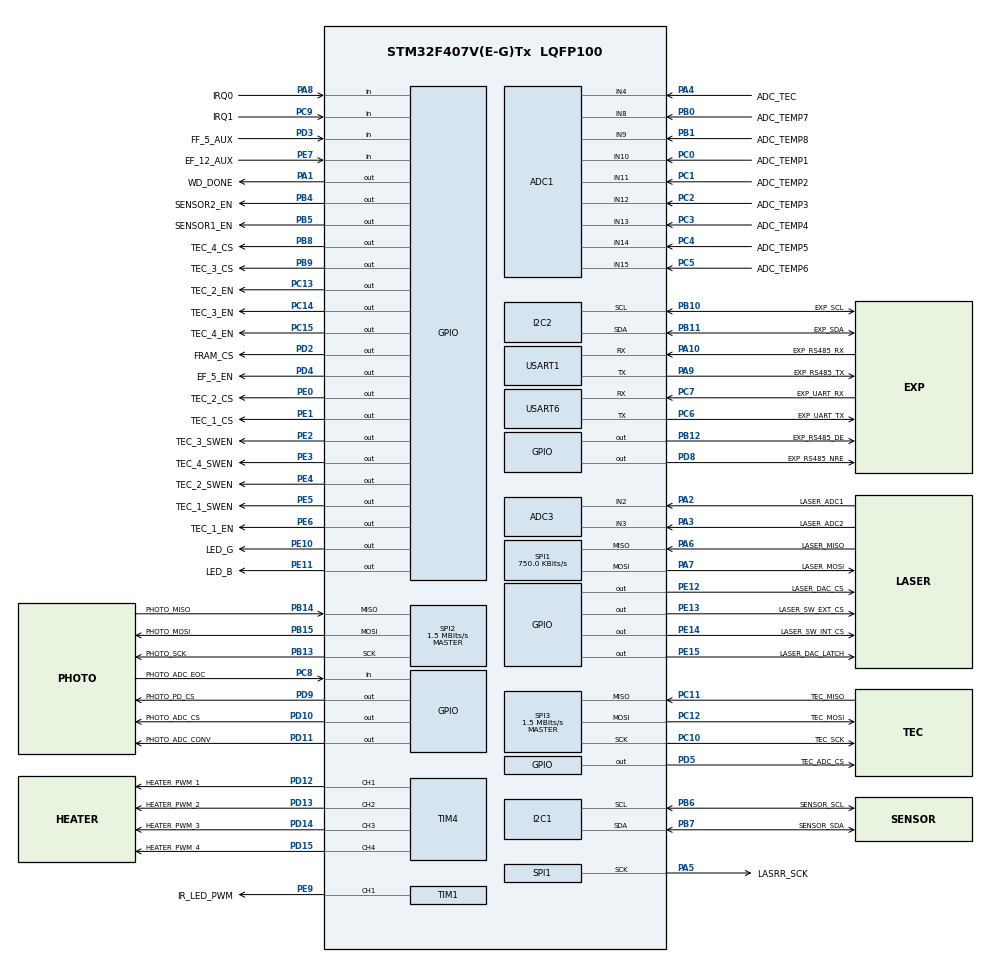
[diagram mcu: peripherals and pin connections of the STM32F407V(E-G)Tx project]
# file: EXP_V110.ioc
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ADC1.Channel-0\#ChannelRegularConversion=ADC_CHANNEL_10
ADC1.Channel-1\#ChannelRegularConversion=ADC_CHANNEL_11
ADC1.Channel-2\#ChannelRegularConversion=ADC_CHANNEL_12
ADC1.Channel-3\#ChannelRegularConversion=ADC_CHANNEL_13
ADC1.Channel-4\#ChannelRegularConversion=ADC_CHANNEL_14
ADC1.Channel-5\#ChannelRegularConversion=ADC_CHANNEL_15
ADC1.Channel-6\#ChannelRegularConversion=ADC_CHANNEL_8
ADC1.Channel-7\#ChannelRegularConversion=ADC_CHANNEL_9
ADC1.ContinuousConvMode=ENABLE
ADC1.DMAContinuousRequests=ENABLE
ADC1.EOCSelection=ADC_EOC_SEQ_CONV
ADC1.InjNumberOfConversion=0
ADC1.NbrOfConversion=8
ADC1.NbrOfConversionFlag=1
ADC1.Rank-0\#ChannelRegularConversion=1
ADC1.Rank-1\#ChannelRegularConversion=2
ADC1.Rank-2\#ChannelRegularConversion=3
ADC1.Rank-3\#ChannelRegularConversion=4
ADC1.Rank-4\#ChannelRegularConversion=5
ADC1.Rank-5\#ChannelRegularConversion=6
ADC1.Rank-6\#ChannelRegularConversion=7
ADC1.Rank-7\#ChannelRegularConversion=8
ADC1.SamplingTime-0\#ChannelRegularConversion=ADC_SAMPLETIME_15CYCLES
ADC1.SamplingTime-1\#ChannelRegularConversion=ADC_SAMPLETIME_15CYCLES
ADC1.SamplingTime-2\#ChannelRegularConversion=ADC_SAMPLETIME_15CYCLES
ADC1.SamplingTime-3\#ChannelRegularConversion=ADC_SAMPLETIME_15CYCLES
ADC1.SamplingTime-4\#ChannelRegularConversion=ADC_SAMPLETIME_15CYCLES
ADC1.SamplingTime-5\#ChannelRegularConversion=ADC_SAMPLETIME_15CYCLES
ADC1.SamplingTime-6\#ChannelRegularConversion=ADC_SAMPLETIME_15CYCLES
ADC1.SamplingTime-7\#ChannelRegularConversion=ADC_SAMPLETIME_15CYCLES
ADC1.ScanConvMode=ENABLE
ADC1.master=1
ADC3.Channel-0\#ChannelRegularConversion=ADC_CHANNEL_2
ADC3.NbrOfConversionFlag=1
ADC3.Rank-0\#ChannelRegularConversion=1
ADC3.SamplingTime-0\#ChannelRegularConversion=ADC_SAMPLETIME_3CYCLES
Dma.ADC1.0.Direction=DMA_PERIPH_TO_MEMORY
Dma.ADC1.0.FIFOMode=DMA_FIFOMODE_DISABLE
Dma.ADC1.0.Instance=DMA2_Stream0
Dma.ADC1.0.MemDataAlignment=DMA_MDATAALIGN_HALFWORD
Dma.ADC1.0.MemInc=DMA_MINC_ENABLE
Dma.ADC1.0.Mode=DMA_CIRCULAR
Dma.ADC1.0.PeriphDataAlignment=DMA_PDATAALIGN_HALFWORD
Dma.ADC1.0.PeriphInc=DMA_PINC_DISABLE
Dma.ADC1.0.Priority=DMA_PRIORITY_MEDIUM
Dma.Request0=ADC1
I2C2.OwnAddress=0x12
Mcu.Family=STM32F4
Mcu.Name=STM32F407V(E-G)Tx
Mcu.Package=LQFP100
NVIC.DMA2_Stream0_IRQn=true\:0\:0\:false\:false\:true\:false\:true\:true
NVIC.I2C2_ER_IRQn=true\:0\:0\:false\:false\:true\:true\:true\:true
NVIC.I2C2_EV_IRQn=true\:0\:0\:false\:false\:true\:true\:true\:true
NVIC.PriorityGroup=NVIC_PRIORITYGROUP_4
NVIC.USART1_IRQn=true\:0\:0\:false\:false\:true\:true\:true\:true
NVIC.USART6_IRQn=true\:0\:0\:false\:false\:true\:true\:true\:true
PA0-WKUP.GPIO_Label=WD_WAKE
PA0-WKUP.Mode=SYS_WakeUp0
PA0-WKUP.Signal=SYS_WKUP
PA1.GPIO_Label=WD_DONE
PA1.Signal=GPIO_Output
PA10.GPIO_Label=EXP_RS485_RX
PA10.Mode=Asynchronous
PA10.Signal=USART1_RX
PA13.Mode=Serial_Wire
PA13.Signal=SYS_JTMS-SWDIO
PA14.Mode=Serial_Wire
PA14.Signal=SYS_JTCK-SWCLK
PA2.GPIO_Label=LASER_ADC1
PA2.Signal=ADCx_IN2
PA3.GPIO_Label=LASER_ADC2
PA3.Signal=ADCx_IN3
PA4.GPIO_Label=ADC_TEC
PA4.Signal=ADCx_IN4
PA5.GPIO_Label=LASRR_SCK
PA5.GPIO_PuPd=GPIO_NOPULL
PA5.Mode=Full_Duplex_Master
PA5.Signal=SPI1_SCK
PA6.GPIO_Label=LASER_MISO
PA6.GPIO_PuPd=GPIO_NOPULL
PA6.Mode=Full_Duplex_Master
PA6.Signal=SPI1_MISO
PA7.GPIO_Label=LASER_MOSI
PA7.GPIO_PuPd=GPIO_NOPULL
PA7.Mode=Full_Duplex_Master
PA7.Signal=SPI1_MOSI
PA8.GPIO_Label=IRQ0
PA8.Signal=GPIO_Input
PA9.GPIO_Label=EXP_RS485_TX
PA9.Mode=Asynchronous
PA9.Signal=USART1_TX
PB0.GPIO_Label=ADC_TEMP7
PB0.Signal=ADCx_IN8
PB1.GPIO_Label=ADC_TEMP8
PB1.Signal=ADCx_IN9
PB10.GPIO_Label=EXP_SCL
PB10.Mode=I2C
PB10.Signal=I2C2_SCL
PB11.GPIO_Label=EXP_SDA
PB11.Mode=I2C
PB11.Signal=I2C2_SDA
PB12.GPIO_Label=EXP_RS485_DE
PB12.PinState=GPIO_PIN_SET
PB12.Signal=GPIO_Output
PB13.GPIO_Label=PHOTO_SCK
PB13.Mode=Full_Duplex_Master
PB13.Signal=SPI2_SCK
PB14.GPIO_Label=PHOTO_MISO
PB14.Mode=Full_Duplex_Master
PB14.Signal=SPI2_MISO
PB15.GPIO_Label=PHOTO_MOSI
PB15.Mode=Full_Duplex_Master
PB15.Signal=SPI2_MOSI
PB4.GPIO_Label=SENSOR2_EN
PB4.Signal=GPIO_Output
PB5.GPIO_Label=SENSOR1_EN
PB5.Signal=GPIO_Output
PB6.GPIO_Label=SENSOR_SCL
PB6.Mode=I2C
PB6.Signal=I2C1_SCL
PB7.GPIO_Label=SENSOR_SDA
PB7.Mode=I2C
PB7.Signal=I2C1_SDA
PB8.GPIO_Label=TEC_4_CS
PB8.PinState=GPIO_PIN_SET
PB8.Signal=GPIO_Output
PB9.GPIO_Label=TEC_3_CS
PB9.PinState=GPIO_PIN_SET
PB9.Signal=GPIO_Output
PC0.GPIO_Label=ADC_TEMP1
PC0.Signal=ADCx_IN10
PC1.GPIO_Label=ADC_TEMP2
PC1.Signal=ADCx_IN11
PC10.GPIO_Label=TEC_SCK
PC10.Mode=Full_Duplex_Master
PC10.Signal=SPI3_SCK
PC11.GPIO_Label=TEC_MISO
PC11.Mode=Full_Duplex_Master
PC11.Signal=SPI3_MISO
PC12.GPIO_Label=TEC_MOSI
PC12.Mode=Full_Duplex_Master
PC12.Signal=SPI3_MOSI
PC13-ANTI_TAMP.GPIO_Label=TEC_2_EN
PC13-ANTI_TAMP.Signal=GPIO_Output
PC14-OSC32_IN.GPIO_Label=TEC_3_EN
PC14-OSC32_IN.Signal=GPIO_Output
PC15-OSC32_OUT.GPIO_Label=TEC_4_EN
PC15-OSC32_OUT.Signal=GPIO_Output
PC2.GPIO_Label=ADC_TEMP3
PC2.Signal=ADCx_IN12
PC3.GPIO_Label=ADC_TEMP4
PC3.Signal=ADCx_IN13
PC4.GPIO_Label=ADC_TEMP5
PC4.Signal=ADCx_IN14
PC5.GPIO_Label=ADC_TEMP6
PC5.Signal=ADCx_IN15
PC6.GPIO_Label=EXP_UART_TX
PC6.Mode=Asynchronous
PC6.Signal=USART6_TX
PC7.GPIO_Label=EXP_UART_RX
PC7.Mode=Asynchronous
PC7.Signal=USART6_RX
PC8.GPIO_Label=PHOTO_ADC_EOC
PC8.GPIO_PuPd=GPIO_PULLUP
PC8.Signal=GPIO_Input
PC9.GPIO_Label=IRQ1
PC9.Signal=GPIO_Input
PD10.GPIO_Label=PHOTO_ADC_CS
PD10.PinState=GPIO_PIN_SET
PD10.Signal=GPIO_Output
PD11.GPIO_Label=PHOTO_ADC_CONV
PD11.PinState=GPIO_PIN_SET
PD11.Signal=GPIO_Output
PD12.GPIO_Label=HEATER_PWM_1
PD12.Signal=S_TIM4_CH1
PD13.GPIO_Label=HEATER_PWM_2
PD13.Signal=S_TIM4_CH2
PD14.GPIO_Label=HEATER_PWM_3
PD14.Signal=S_TIM4_CH3
PD15.GPIO_Label=HEATER_PWM_4
PD15.Signal=S_TIM4_CH4
PD2.GPIO_Label=FRAM_CS
PD2.Signal=GPIO_Output
PD3.GPIO_Label=FF_5_AUX
PD3.Signal=GPIO_Input
PD4.GPIO_Label=EF_5_EN
PD4.Signal=GPIO_Output
PD5.GPIO_Label=TEC_ADC_CS
PD5.Signal=GPIO_Output
PD8.GPIO_Label=EXP_RS485_NRE
PD8.Signal=GPIO_Output
PD9.GPIO_Label=PHOTO_PD_CS
PD9.PinState=GPIO_PIN_SET
PD9.Signal=GPIO_Output
PE0.GPIO_Label=TEC_2_CS
PE0.PinState=GPIO_PIN_SET
PE0.Signal=GPIO_Output
PE1.GPIO_Label=TEC_1_CS
PE1.GPIO_PuPd=GPIO_NOPULL
PE1.PinState=GPIO_PIN_SET
PE1.Signal=GPIO_Output
PE10.GPIO_Label=LED_G
PE10.Signal=GPIO_Output
PE11.GPIO_Label=LED_B
PE11.Signal=GPIO_Output
PE12.GPIO_Label=LASER_DAC_CS
PE12.PinState=GPIO_PIN_SET
PE12.Signal=GPIO_Output
PE13.GPIO_Label=LASER_SW_EXT_CS
PE13.PinState=GPIO_PIN_SET
PE13.Signal=GPIO_Output
PE14.GPIO_Label=LASER_SW_INT_CS
PE14.PinState=GPIO_PIN_SET
PE14.Signal=GPIO_Output
PE15.GPIO_Label=LASER_DAC_LATCH
PE15.PinState=GPIO_PIN_SET
PE15.Signal=GPIO_Output
PE2.GPIO_Label=TEC_3_SWEN
PE2.GPIO_PuPd=GPIO_PULLDOWN
PE2.Signal=GPIO_Output
PE3.GPIO_Label=TEC_4_SWEN
PE3.Signal=GPIO_Output
PE4.GPIO_Label=TEC_2_SWEN
PE4.Signal=GPIO_Output
PE5.GPIO_Label=TEC_1_SWEN
PE5.GPIO_PuPd=GPIO_PULLDOWN
PE5.Signal=GPIO_Output
PE6.GPIO_Label=TEC_1_EN
PE6.Signal=GPIO_Output
PE7.GPIO_Label=EF_12_AUX
PE7.Signal=GPIO_Input
PE9.GPIO_Label=IR_LED_PWM
PE9.Signal=S_TIM1_CH1
PH0-OSC_IN.Mode=HSE-External-Oscillator
PH0-OSC_IN.Signal=RCC_OSC_IN
PH1-OSC_OUT.Mode=HSE-External-Oscillator
PH1-OSC_OUT.Signal=RCC_OSC_OUT
ProjectManager.HeapSize=0x200
ProjectManager.StackSize=0x400
ProjectManager.TargetToolchain=STM32CubeIDE
RCC.48MHZClocksFreq_Value=36000000
RCC.AHBFreq_Value=24000000
RCC.APB1Freq_Value=24000000
RCC.APB1TimFreq_Value=24000000
RCC.APB2Freq_Value=24000000
RCC.APB2TimFreq_Value=24000000
RCC.CortexFreq_Value=24000000
RCC.HCLKFreq_Value=24000000
RCC.HSE_VALUE=8000000
RCC.HSI_VALUE=16000000
RCC.LSE_VALUE=32768
RCC.PLLM=4
RCC.PLLN=72
RCC.PLLP=RCC_PLLP_DIV6
RCC.PLLSourceVirtual=RCC_PLLSOURCE_HSE
RCC.SYSCLKFreq_VALUE=24000000
RCC.SYSCLKSource=RCC_SYSCLKSOURCE_PLLCLK
RCC.VCOOutputFreq_Value=144000000
SH.ADCx_IN10.0=ADC1_IN10,IN10
SH.ADCx_IN11.0=ADC1_IN11,IN11
SH.ADCx_IN12.0=ADC1_IN12,IN12
SH.ADCx_IN13.0=ADC1_IN13,IN13
SH.ADCx_IN14.0=ADC1_IN14,IN14
SH.ADCx_IN15.0=ADC1_IN15,IN15
SH.ADCx_IN2.0=ADC3_IN2,IN2
SH.ADCx_IN3.0=ADC3_IN3,IN3
SH.ADCx_IN4.0=ADC1_IN4,IN4
SH.ADCx_IN8.0=ADC1_IN8,IN8
SH.ADCx_IN9.0=ADC1_IN9,IN9
SH.S_TIM1_CH1.0=TIM1_CH1,PWM Generation1 CH1
SH.S_TIM4_CH1.0=TIM4_CH1,Output Compare1 CH1
SH.S_TIM4_CH2.0=TIM4_CH2,Output Compare2 CH2
SH.S_TIM4_CH3.0=TIM4_CH3,Output Compare3 CH3
SH.S_TIM4_CH4.0=TIM4_CH4,Output Compare4 CH4
SPI1.BaudRatePrescaler=SPI_BAUDRATEPRESCALER_32
SPI1.CLKPhase=SPI_PHASE_2EDGE
SPI1.CRCCalculation=SPI_CRCCALCULATION_DISABLE
SPI1.CalculateBaudRate=750.0 KBits/s
SPI1.Direction=SPI_DIRECTION_2LINES
SPI1.FirstBit=SPI_FIRSTBIT_MSB
SPI1.Mode=SPI_MODE_MASTER
SPI1.VirtualType=VM_MASTER
SPI2.BaudRatePrescaler=SPI_BAUDRATEPRESCALER_16
SPI2.CLKPhase=SPI_PHASE_2EDGE
SPI2.CalculateBaudRate=1.5 MBits/s
SPI2.Direction=SPI_DIRECTION_2LINES
SPI2.Mode=SPI_MODE_MASTER
SPI2.VirtualType=VM_MASTER
SPI3.BaudRatePrescaler=SPI_BAUDRATEPRESCALER_16
SPI3.CalculateBaudRate=1.5 MBits/s
SPI3.Direction=SPI_DIRECTION_2LINES
SPI3.Mode=SPI_MODE_MASTER
SPI3.VirtualType=VM_MASTER
TIM1.Channel-PWM\ Generation1\ CH1=TIM_CHANNEL_1
TIM1.Period=9999
TIM1.Prescaler=83
TIM3.Period=9999
TIM3.Prescaler=83
TIM4.Channel-Output\ Compare1\ CH1=TIM_CHANNEL_1
TIM4.Channel-Output\ Compare2\ CH2=TIM_CHANNEL_2
TIM4.Channel-Output\ Compare3\ CH3=TIM_CHANNEL_3
TIM4.Channel-Output\ Compare4\ CH4=TIM_CHANNEL_4
USART1.VirtualMode=VM_ASYNC
USART6.VirtualMode=VM_ASYNC
VP_TIM1_VS_ClockSourceINT.Mode=Internal
VP_TIM3_VS_ClockSourceINT.Mode=Internal
board=custom

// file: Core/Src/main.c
/* USER CODE BEGIN Header */
/**
 ******************************************************************************
 * @file           : main.c
 * @brief          : Main program body
 ******************************************************************************
 * @attention
 *
 * Copyright (c) 2024 STMicroelectronics.
 * All rights reserved.
 *
 * This software is licensed under terms that can be found in the LICENSE file
 * in the root directory of this software component.
 * If no LICENSE file comes with this software, it is provided AS-IS.
 *
 ******************************************************************************
 */
/* USER CODE END Header */
#include "main.h"
#include "stdio.h"
/* USER CODE BEGIN Includes */
#include "board.h"
#include "scheduler.h"
#include "watchdog.h"
#include "status_led.h"
#include "command.h"
#include "cmdline.h"
#include "uart.h"
#include "ntc.h"
#include "temperature.h"
#include "copc.h"
#include "sensor_i2c.h"
#include "register.h"
#include "i2c_slave.h"
#include "i2c.h"
#include "date_time.h"
#include "auto_run.h"
#include "laser_board.h"
#include "photo_board.h"
#include "mb85rs2mt.h"
#include "lt8722.h"
#include "cli_command.h"
#include "min_process.h"
#include "uart_driver.h"
/* USER CODE END Includes */

ADC_HandleTypeDef hadc3;

TIM_HandleTypeDef htim4;

void SystemClock_Config(void);
static void MX_GPIO_Init(void);
static void MX_DMA_Init(void);
static void MX_SPI1_Init(void);
static void MX_ADC1_Init(void);
static void MX_TIM1_Init(void);
static void MX_TIM3_Init(void);
static void MX_I2C2_Init(void);
static void MX_SPI3_Init(void);
static void MX_SPI2_Init(void);
static void MX_USART6_UART_Init(void);
static void MX_ADC3_Init(void);
static void MX_TIM4_Init(void);
static void MX_USART1_UART_Init(void);
static void MX_I2C1_Init(void);

/* USER CODE BEGIN 0 */
#define PRINTF_USART6 int __io_putchar(int data)
/* USER CODE END 0 */

int main(void)
{

  /* MCU Configuration--------------------------------------------------------*/

  /* Reset of all peripherals, Initializes the Flash interface and the Systick. */
  HAL_Init();

  /* Configure the system clock */
  SystemClock_Config();

  /* Initialize all configured peripherals */
  MX_GPIO_Init();
  MX_DMA_Init();
  MX_SPI1_Init();
  MX_ADC1_Init();
  MX_TIM1_Init();
  MX_TIM3_Init();
  MX_I2C2_Init();
  MX_SPI3_Init();
  MX_SPI2_Init();
  MX_USART6_UART_Init();
  MX_ADC3_Init();
  MX_TIM4_Init();
  MX_USART1_UART_Init();
  MX_I2C1_Init();
  /* USER CODE BEGIN 2 */

  // Initialize for device
//  MB85RS2MT_Init(&fram);
//  adg1414_init(&exp_adg1414);

  // Initialize all preset for schedule task
//  Ex_Watchdog_Init();
//  LED_Status_Init();
//  CommandLine_Init(EXP_UART_HANDLE);
//  CLI_Command_Init(EXP_UART_HANDLE);
//  NTC_DMA_ADC_Init();
//  Laser_board_init();
//  Photo_board_init();

  UART_Driver_Init();
  MIN_Process_Init();

  SCH_Initialize();

  // Create task scheduler
//  Ex_Watchdog_CreateTask();
//  LED_Status_CreateTask();
//  CommandLine_CreateTask();
//  CLI_Command_CreateTask();
//  Temperature_GetSet_CreateTask();
  // sensor_i2c_create_task();
//  AutoRun_CreateTask();
//  SoftTime_CreateTask();
  MIN_CreateTask();

  SCH_StartSchedular();
  /* USER CODE END 2 */

  /* Infinite loop */
  /* USER CODE BEGIN WHILE */
  while (1)
  {
	  SCH_HandleScheduledTask();
    /* USER CODE END WHILE */

  }
}

void SystemClock_Config(void)
{
  LL_FLASH_SetLatency(LL_FLASH_LATENCY_0);
  while(LL_FLASH_GetLatency()!= LL_FLASH_LATENCY_0)
  {
  }
  LL_PWR_SetRegulVoltageScaling(LL_PWR_REGU_VOLTAGE_SCALE1);
  LL_RCC_HSE_Enable();

   /* Wait till HSE is ready */
  while(LL_RCC_HSE_IsReady() != 1)
  {

  }
  LL_RCC_PLL_ConfigDomain_SYS(LL_RCC_PLLSOURCE_HSE, LL_RCC_PLLM_DIV_4, 72, LL_RCC_PLLP_DIV_6);
  LL_RCC_PLL_Enable();

   /* Wait till PLL is ready */
  while(LL_RCC_PLL_IsReady() != 1)
  {

  }
  while (LL_PWR_IsActiveFlag_VOS() == 0)
  {
  }
  LL_RCC_SetAHBPrescaler(LL_RCC_SYSCLK_DIV_1);
  LL_RCC_SetAPB1Prescaler(LL_RCC_APB1_DIV_1);
  LL_RCC_SetAPB2Prescaler(LL_RCC_APB2_DIV_1);
  LL_RCC_SetSysClkSource(LL_RCC_SYS_CLKSOURCE_PLL);

   /* Wait till System clock is ready */
  while(LL_RCC_GetSysClkSource() != LL_RCC_SYS_CLKSOURCE_STATUS_PLL)
  {

  }
  LL_SetSystemCoreClock(24000000);

   /* Update the time base */
  if (HAL_InitTick (TICK_INT_PRIORITY) != HAL_OK)
  {
    Error_Handler();
  }
}

static void MX_ADC1_Init(void)
{

  LL_ADC_InitTypeDef ADC_InitStruct = {0};
  LL_ADC_REG_InitTypeDef ADC_REG_InitStruct = {0};
  LL_ADC_CommonInitTypeDef ADC_CommonInitStruct = {0};

  LL_GPIO_InitTypeDef GPIO_InitStruct = {0};

  /* Peripheral clock enable */
  LL_APB2_GRP1_EnableClock(LL_APB2_GRP1_PERIPH_ADC1);

  LL_AHB1_GRP1_EnableClock(LL_AHB1_GRP1_PERIPH_GPIOC);
  LL_AHB1_GRP1_EnableClock(LL_AHB1_GRP1_PERIPH_GPIOA);
  LL_AHB1_GRP1_EnableClock(LL_AHB1_GRP1_PERIPH_GPIOB);
  /**ADC1 GPIO Configuration
  PC0   ------> ADC1_IN10
  PC1   ------> ADC1_IN11
  PC2   ------> ADC1_IN12
  PC3   ------> ADC1_IN13
  PA4   ------> ADC1_IN4
  PC4   ------> ADC1_IN14
  PC5   ------> ADC1_IN15
  PB0   ------> ADC1_IN8
  PB1   ------> ADC1_IN9
  */
  GPIO_InitStruct.Pin = ADC_TEMP1_Pin|ADC_TEMP2_Pin|ADC_TEMP3_Pin|ADC_TEMP4_Pin
                          |ADC_TEMP5_Pin|ADC_TEMP6_Pin;
  GPIO_InitStruct.Mode = LL_GPIO_MODE_ANALOG;
  GPIO_InitStruct.Pull = LL_GPIO_PULL_NO;
  LL_GPIO_Init(GPIOC, &GPIO_InitStruct);

  GPIO_InitStruct.Pin = ADC_TEC_Pin;
  GPIO_InitStruct.Mode = LL_GPIO_MODE_ANALOG;
  GPIO_InitStruct.Pull = LL_GPIO_PULL_NO;
  LL_GPIO_Init(ADC_TEC_GPIO_Port, &GPIO_InitStruct);

  GPIO_InitStruct.Pin = ADC_TEMP7_Pin|ADC_TEMP8_Pin;
  GPIO_InitStruct.Mode = LL_GPIO_MODE_ANALOG;
  GPIO_InitStruct.Pull = LL_GPIO_PULL_NO;
  LL_GPIO_Init(GPIOB, &GPIO_InitStruct);

  /* ADC1 DMA Init */

  /* ADC1 Init */
  LL_DMA_SetChannelSelection(DMA2, LL_DMA_STREAM_0, LL_DMA_CHANNEL_0);

  LL_DMA_SetDataTransferDirection(DMA2, LL_DMA_STREAM_0, LL_DMA_DIRECTION_PERIPH_TO_MEMORY);

  LL_DMA_SetStreamPriorityLevel(DMA2, LL_DMA_STREAM_0, LL_DMA_PRIORITY_MEDIUM);

  LL_DMA_SetMode(DMA2, LL_DMA_STREAM_0, LL_DMA_MODE_CIRCULAR);

  LL_DMA_SetPeriphIncMode(DMA2, LL_DMA_STREAM_0, LL_DMA_PERIPH_NOINCREMENT);

  LL_DMA_SetMemoryIncMode(DMA2, LL_DMA_STREAM_0, LL_DMA_MEMORY_INCREMENT);

  LL_DMA_SetPeriphSize(DMA2, LL_DMA_STREAM_0, LL_DMA_PDATAALIGN_HALFWORD);

  LL_DMA_SetMemorySize(DMA2, LL_DMA_STREAM_0, LL_DMA_MDATAALIGN_HALFWORD);

  LL_DMA_DisableFifoMode(DMA2, LL_DMA_STREAM_0);

  /** Common config
  */
  ADC_InitStruct.Resolution = LL_ADC_RESOLUTION_12B;
  ADC_InitStruct.DataAlignment = LL_ADC_DATA_ALIGN_RIGHT;
  ADC_InitStruct.SequencersScanMode = LL_ADC_SEQ_SCAN_ENABLE;
  LL_ADC_Init(ADC1, &ADC_InitStruct);
  ADC_REG_InitStruct.TriggerSource = LL_ADC_REG_TRIG_SOFTWARE;
  ADC_REG_InitStruct.SequencerLength = LL_ADC_REG_SEQ_SCAN_ENABLE_8RANKS;
  ADC_REG_InitStruct.SequencerDiscont = LL_ADC_REG_SEQ_DISCONT_DISABLE;
  ADC_REG_InitStruct.ContinuousMode = LL_ADC_REG_CONV_CONTINUOUS;
  ADC_REG_InitStruct.DMATransfer = LL_ADC_REG_DMA_TRANSFER_UNLIMITED;
  LL_ADC_REG_Init(ADC1, &ADC_REG_InitStruct);
  LL_ADC_REG_SetFlagEndOfConversion(ADC1, LL_ADC_REG_FLAG_EOC_SEQUENCE_CONV);
  ADC_CommonInitStruct.CommonClock = LL_ADC_CLOCK_SYNC_PCLK_DIV2;
  ADC_CommonInitStruct.Multimode = LL_ADC_MULTI_INDEPENDENT;
  LL_ADC_CommonInit(__LL_ADC_COMMON_INSTANCE(ADC1), &ADC_CommonInitStruct);

  /** Configure Regular Channel
  */
  LL_ADC_REG_SetSequencerRanks(ADC1, LL_ADC_REG_RANK_1, LL_ADC_CHANNEL_10);
  LL_ADC_SetChannelSamplingTime(ADC1, LL_ADC_CHANNEL_10, LL_ADC_SAMPLINGTIME_15CYCLES);

  /** Configure Regular Channel
  */
  LL_ADC_REG_SetSequencerRanks(ADC1, LL_ADC_REG_RANK_2, LL_ADC_CHANNEL_11);
  LL_ADC_SetChannelSamplingTime(ADC1, LL_ADC_CHANNEL_11, LL_ADC_SAMPLINGTIME_15CYCLES);

  /** Configure Regular Channel
  */
  LL_ADC_REG_SetSequencerRanks(ADC1, LL_ADC_REG_RANK_3, LL_ADC_CHANNEL_12);
  LL_ADC_SetChannelSamplingTime(ADC1, LL_ADC_CHANNEL_12, LL_ADC_SAMPLINGTIME_15CYCLES);

  /** Configure Regular Channel
  */
  LL_ADC_REG_SetSequencerRanks(ADC1, LL_ADC_REG_RANK_4, LL_ADC_CHANNEL_13);
  LL_ADC_SetChannelSamplingTime(ADC1, LL_ADC_CHANNEL_13, LL_ADC_SAMPLINGTIME_15CYCLES);

  /** Configure Regular Channel
  */
  LL_ADC_REG_SetSequencerRanks(ADC1, LL_ADC_REG_RANK_5, LL_ADC_CHANNEL_14);
  LL_ADC_SetChannelSamplingTime(ADC1, LL_ADC_CHANNEL_14, LL_ADC_SAMPLINGTIME_15CYCLES);

  /** Configure Regular Channel
  */
  LL_ADC_REG_SetSequencerRanks(ADC1, LL_ADC_REG_RANK_6, LL_ADC_CHANNEL_15);
  LL_ADC_SetChannelSamplingTime(ADC1, LL_ADC_CHANNEL_15, LL_ADC_SAMPLINGTIME_15CYCLES);

  /** Configure Regular Channel
  */
  LL_ADC_REG_SetSequencerRanks(ADC1, LL_ADC_REG_RANK_7, LL_ADC_CHANNEL_8);
  LL_ADC_SetChannelSamplingTime(ADC1, LL_ADC_CHANNEL_8, LL_ADC_SAMPLINGTIME_15CYCLES);

  /** Configure Regular Channel
  */
  LL_ADC_REG_SetSequencerRanks(ADC1, LL_ADC_REG_RANK_8, LL_ADC_CHANNEL_9);
  LL_ADC_SetChannelSamplingTime(ADC1, LL_ADC_CHANNEL_9, LL_ADC_SAMPLINGTIME_15CYCLES);

}

static void MX_ADC3_Init(void)
{

  ADC_ChannelConfTypeDef sConfig = {0};

  /** Configure the global features of the ADC (Clock, Resolution, Data Alignment and number of conversion)
  */
  hadc3.Instance = ADC3;
  hadc3.Init.ClockPrescaler = ADC_CLOCK_SYNC_PCLK_DIV2;
  hadc3.Init.Resolution = ADC_RESOLUTION_12B;
  hadc3.Init.ScanConvMode = DISABLE;
  hadc3.Init.ContinuousConvMode = DISABLE;
  hadc3.Init.DiscontinuousConvMode = DISABLE;
  hadc3.Init.ExternalTrigConvEdge = ADC_EXTERNALTRIGCONVEDGE_NONE;
  hadc3.Init.ExternalTrigConv = ADC_SOFTWARE_START;
  hadc3.Init.DataAlign = ADC_DATAALIGN_RIGHT;
  hadc3.Init.NbrOfConversion = 1;
  hadc3.Init.DMAContinuousRequests = DISABLE;
  hadc3.Init.EOCSelection = ADC_EOC_SINGLE_CONV;
  if (HAL_ADC_Init(&hadc3) != HAL_OK)
  {
    Error_Handler();
  }

  /** Configure for the selected ADC regular channel its corresponding rank in the sequencer and its sample time.
  */
  sConfig.Channel = ADC_CHANNEL_2;
  sConfig.Rank = 1;
  sConfig.SamplingTime = ADC_SAMPLETIME_3CYCLES;
  if (HAL_ADC_ConfigChannel(&hadc3, &sConfig) != HAL_OK)
  {
    Error_Handler();
  }

}

static void MX_I2C1_Init(void)
{

  LL_I2C_InitTypeDef I2C_InitStruct = {0};

  LL_GPIO_InitTypeDef GPIO_InitStruct = {0};

  LL_AHB1_GRP1_EnableClock(LL_AHB1_GRP1_PERIPH_GPIOB);
  /**I2C1 GPIO Configuration
  PB6   ------> I2C1_SCL
  PB7   ------> I2C1_SDA
  */
  GPIO_InitStruct.Pin = SENSOR_SCL_Pin|SENSOR_SDA_Pin;
  GPIO_InitStruct.Mode = LL_GPIO_MODE_ALTERNATE;
  GPIO_InitStruct.Speed = LL_GPIO_SPEED_FREQ_VERY_HIGH;
  GPIO_InitStruct.OutputType = LL_GPIO_OUTPUT_OPENDRAIN;
  GPIO_InitStruct.Pull = LL_GPIO_PULL_NO;
  GPIO_InitStruct.Alternate = LL_GPIO_AF_4;
  LL_GPIO_Init(GPIOB, &GPIO_InitStruct);

  /* Peripheral clock enable */
  LL_APB1_GRP1_EnableClock(LL_APB1_GRP1_PERIPH_I2C1);

  /** I2C Initialization
  */
  LL_I2C_DisableOwnAddress2(I2C1);
  LL_I2C_DisableGeneralCall(I2C1);
  LL_I2C_EnableClockStretching(I2C1);
  I2C_InitStruct.PeripheralMode = LL_I2C_MODE_I2C;
  I2C_InitStruct.ClockSpeed = 100000;
  I2C_InitStruct.DutyCycle = LL_I2C_DUTYCYCLE_2;
  I2C_InitStruct.OwnAddress1 = 0;
  I2C_InitStruct.TypeAcknowledge = LL_I2C_ACK;
  I2C_InitStruct.OwnAddrSize = LL_I2C_OWNADDRESS1_7BIT;
  LL_I2C_Init(I2C1, &I2C_InitStruct);
  LL_I2C_SetOwnAddress2(I2C1, 0);

}

static void MX_I2C2_Init(void)
{

  LL_I2C_InitTypeDef I2C_InitStruct = {0};

  LL_GPIO_InitTypeDef GPIO_InitStruct = {0};

  LL_AHB1_GRP1_EnableClock(LL_AHB1_GRP1_PERIPH_GPIOB);
  /**I2C2 GPIO Configuration
  PB10   ------> I2C2_SCL
  PB11   ------> I2C2_SDA
  */
  GPIO_InitStruct.Pin = EXP_SCL_Pin|EXP_SDA_Pin;
  GPIO_InitStruct.Mode = LL_GPIO_MODE_ALTERNATE;
  GPIO_InitStruct.Speed = LL_GPIO_SPEED_FREQ_VERY_HIGH;
  GPIO_InitStruct.OutputType = LL_GPIO_OUTPUT_OPENDRAIN;
  GPIO_InitStruct.Pull = LL_GPIO_PULL_NO;
  GPIO_InitStruct.Alternate = LL_GPIO_AF_4;
  LL_GPIO_Init(GPIOB, &GPIO_InitStruct);

  /* Peripheral clock enable */
  LL_APB1_GRP1_EnableClock(LL_APB1_GRP1_PERIPH_I2C2);

  /* I2C2 interrupt Init */
  NVIC_SetPriority(I2C2_EV_IRQn, NVIC_EncodePriority(NVIC_GetPriorityGrouping(),0, 0));
  NVIC_EnableIRQ(I2C2_EV_IRQn);
  NVIC_SetPriority(I2C2_ER_IRQn, NVIC_EncodePriority(NVIC_GetPriorityGrouping(),0, 0));
  NVIC_EnableIRQ(I2C2_ER_IRQn);

  /** I2C Initialization
  */
  LL_I2C_DisableOwnAddress2(I2C2);
  LL_I2C_DisableGeneralCall(I2C2);
  LL_I2C_EnableClockStretching(I2C2);
  I2C_InitStruct.PeripheralMode = LL_I2C_MODE_I2C;
  I2C_InitStruct.ClockSpeed = 100000;
  I2C_InitStruct.DutyCycle = LL_I2C_DUTYCYCLE_2;
  I2C_InitStruct.OwnAddress1 = 36;
  I2C_InitStruct.TypeAcknowledge = LL_I2C_ACK;
  I2C_InitStruct.OwnAddrSize = LL_I2C_OWNADDRESS1_7BIT;
  LL_I2C_Init(I2C2, &I2C_InitStruct);
  LL_I2C_SetOwnAddress2(I2C2, 0);
  /* USER CODE BEGIN I2C2_Init 2 */
  LL_I2C_EnableIT_EVT(I2C2);
  //  LL_I2C_EnableIT_ERR(I2C2);
  LL_I2C_Enable(I2C2);
  /* USER CODE END I2C2_Init 2 */

}

static void MX_SPI1_Init(void)
{

  LL_SPI_InitTypeDef SPI_InitStruct = {0};

  LL_GPIO_InitTypeDef GPIO_InitStruct = {0};

  /* Peripheral clock enable */
  LL_APB2_GRP1_EnableClock(LL_APB2_GRP1_PERIPH_SPI1);

  LL_AHB1_GRP1_EnableClock(LL_AHB1_GRP1_PERIPH_GPIOA);
  /**SPI1 GPIO Configuration
  PA5   ------> SPI1_SCK
  PA6   ------> SPI1_MISO
  PA7   ------> SPI1_MOSI
  */
  GPIO_InitStruct.Pin = LASRR_SCK_Pin|LASER_MISO_Pin|LASER_MOSI_Pin;
  GPIO_InitStruct.Mode = LL_GPIO_MODE_ALTERNATE;
  GPIO_InitStruct.Speed = LL_GPIO_SPEED_FREQ_VERY_HIGH;
  GPIO_InitStruct.OutputType = LL_GPIO_OUTPUT_PUSHPULL;
  GPIO_InitStruct.Pull = LL_GPIO_PULL_NO;
  GPIO_InitStruct.Alternate = LL_GPIO_AF_5;
  LL_GPIO_Init(GPIOA, &GPIO_InitStruct);

  /* SPI1 parameter configuration*/
  SPI_InitStruct.TransferDirection = LL_SPI_FULL_DUPLEX;
  SPI_InitStruct.Mode = LL_SPI_MODE_MASTER;
  SPI_InitStruct.DataWidth = LL_SPI_DATAWIDTH_8BIT;
  SPI_InitStruct.ClockPolarity = LL_SPI_POLARITY_LOW;
  SPI_InitStruct.ClockPhase = LL_SPI_PHASE_2EDGE;
  SPI_InitStruct.NSS = LL_SPI_NSS_SOFT;
  SPI_InitStruct.BaudRate = LL_SPI_BAUDRATEPRESCALER_DIV32;
  SPI_InitStruct.BitOrder = LL_SPI_MSB_FIRST;
  SPI_InitStruct.CRCCalculation = LL_SPI_CRCCALCULATION_DISABLE;
  SPI_InitStruct.CRCPoly = 10;
  LL_SPI_Init(SPI1, &SPI_InitStruct);
  LL_SPI_SetStandard(SPI1, LL_SPI_PROTOCOL_MOTOROLA);
  /* USER CODE BEGIN SPI1_Init 2 */
  LL_SPI_Enable(SPI1);
  /* USER CODE END SPI1_Init 2 */

}

static void MX_SPI2_Init(void)
{

  LL_SPI_InitTypeDef SPI_InitStruct = {0};

  LL_GPIO_InitTypeDef GPIO_InitStruct = {0};

  /* Peripheral clock enable */
  LL_APB1_GRP1_EnableClock(LL_APB1_GRP1_PERIPH_SPI2);

  LL_AHB1_GRP1_EnableClock(LL_AHB1_GRP1_PERIPH_GPIOB);
  /**SPI2 GPIO Configuration
  PB13   ------> SPI2_SCK
  PB14   ------> SPI2_MISO
  PB15   ------> SPI2_MOSI
  */
  GPIO_InitStruct.Pin = PHOTO_SCK_Pin|PHOTO_MISO_Pin|PHOTO_MOSI_Pin;
  GPIO_InitStruct.Mode = LL_GPIO_MODE_ALTERNATE;
  GPIO_InitStruct.Speed = LL_GPIO_SPEED_FREQ_VERY_HIGH;
  GPIO_InitStruct.OutputType = LL_GPIO_OUTPUT_PUSHPULL;
  GPIO_InitStruct.Pull = LL_GPIO_PULL_NO;
  GPIO_InitStruct.Alternate = LL_GPIO_AF_5;
  LL_GPIO_Init(GPIOB, &GPIO_InitStruct);

  /* SPI2 parameter configuration*/
  SPI_InitStruct.TransferDirection = LL_SPI_FULL_DUPLEX;
  SPI_InitStruct.Mode = LL_SPI_MODE_MASTER;
  SPI_InitStruct.DataWidth = LL_SPI_DATAWIDTH_8BIT;
  SPI_InitStruct.ClockPolarity = LL_SPI_POLARITY_LOW;
  SPI_InitStruct.ClockPhase = LL_SPI_PHASE_2EDGE;
  SPI_InitStruct.NSS = LL_SPI_NSS_SOFT;
  SPI_InitStruct.BaudRate = LL_SPI_BAUDRATEPRESCALER_DIV16;
  SPI_InitStruct.BitOrder = LL_SPI_MSB_FIRST;
  SPI_InitStruct.CRCCalculation = LL_SPI_CRCCALCULATION_DISABLE;
  SPI_InitStruct.CRCPoly = 10;
  LL_SPI_Init(SPI2, &SPI_InitStruct);
  LL_SPI_SetStandard(SPI2, LL_SPI_PROTOCOL_MOTOROLA);
  /* USER CODE BEGIN SPI2_Init 2 */
  LL_SPI_Enable(SPI2);
  /* USER CODE END SPI2_Init 2 */

}

static void MX_SPI3_Init(void)
{

  LL_SPI_InitTypeDef SPI_InitStruct = {0};

  LL_GPIO_InitTypeDef GPIO_InitStruct = {0};

  /* Peripheral clock enable */
  LL_APB1_GRP1_EnableClock(LL_APB1_GRP1_PERIPH_SPI3);

  LL_AHB1_GRP1_EnableClock(LL_AHB1_GRP1_PERIPH_GPIOC);
  /**SPI3 GPIO Configuration
  PC10   ------> SPI3_SCK
  PC11   ------> SPI3_MISO
  PC12   ------> SPI3_MOSI
  */
  GPIO_InitStruct.Pin = TEC_SCK_Pin|TEC_MISO_Pin|TEC_MOSI_Pin;
  GPIO_InitStruct.Mode = LL_GPIO_MODE_ALTERNATE;
  GPIO_InitStruct.Speed = LL_GPIO_SPEED_FREQ_VERY_HIGH;
  GPIO_InitStruct.OutputType = LL_GPIO_OUTPUT_PUSHPULL;
  GPIO_InitStruct.Pull = LL_GPIO_PULL_NO;
  GPIO_InitStruct.Alternate = LL_GPIO_AF_6;
  LL_GPIO_Init(GPIOC, &GPIO_InitStruct);

  /* SPI3 parameter configuration*/
  SPI_InitStruct.TransferDirection = LL_SPI_FULL_DUPLEX;
  SPI_InitStruct.Mode = LL_SPI_MODE_MASTER;
  SPI_InitStruct.DataWidth = LL_SPI_DATAWIDTH_8BIT;
  SPI_InitStruct.ClockPolarity = LL_SPI_POLARITY_LOW;
  SPI_InitStruct.ClockPhase = LL_SPI_PHASE_1EDGE;
  SPI_InitStruct.NSS = LL_SPI_NSS_SOFT;
  SPI_InitStruct.BaudRate = LL_SPI_BAUDRATEPRESCALER_DIV16;
  SPI_InitStruct.BitOrder = LL_SPI_MSB_FIRST;
  SPI_InitStruct.CRCCalculation = LL_SPI_CRCCALCULATION_DISABLE;
  SPI_InitStruct.CRCPoly = 10;
  LL_SPI_Init(SPI3, &SPI_InitStruct);
  LL_SPI_SetStandard(SPI3, LL_SPI_PROTOCOL_MOTOROLA);
  /* USER CODE BEGIN SPI3_Init 2 */
  LL_SPI_Enable(SPI3);
  /* USER CODE END SPI3_Init 2 */

}

static void MX_TIM1_Init(void)
{

  LL_TIM_InitTypeDef TIM_InitStruct = {0};
  LL_TIM_OC_InitTypeDef TIM_OC_InitStruct = {0};
  LL_TIM_BDTR_InitTypeDef TIM_BDTRInitStruct = {0};

  LL_GPIO_InitTypeDef GPIO_InitStruct = {0};

  /* Peripheral clock enable */
  LL_APB2_GRP1_EnableClock(LL_APB2_GRP1_PERIPH_TIM1);

  TIM_InitStruct.Prescaler = 83;
  TIM_InitStruct.CounterMode = LL_TIM_COUNTERMODE_UP;
  TIM_InitStruct.Autoreload = 9999;
  TIM_InitStruct.ClockDivision = LL_TIM_CLOCKDIVISION_DIV1;
  TIM_InitStruct.RepetitionCounter = 0;
  LL_TIM_Init(TIM1, &TIM_InitStruct);
  LL_TIM_DisableARRPreload(TIM1);
  LL_TIM_SetClockSource(TIM1, LL_TIM_CLOCKSOURCE_INTERNAL);
  LL_TIM_OC_EnablePreload(TIM1, LL_TIM_CHANNEL_CH1);
  TIM_OC_InitStruct.OCMode = LL_TIM_OCMODE_PWM1;
  TIM_OC_InitStruct.OCState = LL_TIM_OCSTATE_DISABLE;
  TIM_OC_InitStruct.OCNState = LL_TIM_OCSTATE_DISABLE;
  TIM_OC_InitStruct.CompareValue = 0;
  TIM_OC_InitStruct.OCPolarity = LL_TIM_OCPOLARITY_HIGH;
  TIM_OC_InitStruct.OCNPolarity = LL_TIM_OCPOLARITY_HIGH;
  TIM_OC_InitStruct.OCIdleState = LL_TIM_OCIDLESTATE_LOW;
  TIM_OC_InitStruct.OCNIdleState = LL_TIM_OCIDLESTATE_LOW;
  LL_TIM_OC_Init(TIM1, LL_TIM_CHANNEL_CH1, &TIM_OC_InitStruct);
  LL_TIM_OC_DisableFast(TIM1, LL_TIM_CHANNEL_CH1);
  LL_TIM_SetTriggerOutput(TIM1, LL_TIM_TRGO_RESET);
  LL_TIM_DisableMasterSlaveMode(TIM1);
  TIM_BDTRInitStruct.OSSRState = LL_TIM_OSSR_DISABLE;
  TIM_BDTRInitStruct.OSSIState = LL_TIM_OSSI_DISABLE;
  TIM_BDTRInitStruct.LockLevel = LL_TIM_LOCKLEVEL_OFF;
  TIM_BDTRInitStruct.DeadTime = 0;
  TIM_BDTRInitStruct.BreakState = LL_TIM_BREAK_DISABLE;
  TIM_BDTRInitStruct.BreakPolarity = LL_TIM_BREAK_POLARITY_HIGH;
  TIM_BDTRInitStruct.AutomaticOutput = LL_TIM_AUTOMATICOUTPUT_DISABLE;
  LL_TIM_BDTR_Init(TIM1, &TIM_BDTRInitStruct);
  LL_AHB1_GRP1_EnableClock(LL_AHB1_GRP1_PERIPH_GPIOE);
  /**TIM1 GPIO Configuration
  PE9   ------> TIM1_CH1
  */
  GPIO_InitStruct.Pin = IR_LED_PWM_Pin;
  GPIO_InitStruct.Mode = LL_GPIO_MODE_ALTERNATE;
  GPIO_InitStruct.Speed = LL_GPIO_SPEED_FREQ_LOW;
  GPIO_InitStruct.OutputType = LL_GPIO_OUTPUT_PUSHPULL;
  GPIO_InitStruct.Pull = LL_GPIO_PULL_NO;
  GPIO_InitStruct.Alternate = LL_GPIO_AF_1;
  LL_GPIO_Init(IR_LED_PWM_GPIO_Port, &GPIO_InitStruct);

}

static void MX_TIM3_Init(void)
{

  LL_TIM_InitTypeDef TIM_InitStruct = {0};

  /* Peripheral clock enable */
  LL_APB1_GRP1_EnableClock(LL_APB1_GRP1_PERIPH_TIM3);

  TIM_InitStruct.Prescaler = 83;
  TIM_InitStruct.CounterMode = LL_TIM_COUNTERMODE_UP;
  TIM_InitStruct.Autoreload = 9999;
  TIM_InitStruct.ClockDivision = LL_TIM_CLOCKDIVISION_DIV1;
  LL_TIM_Init(TIM3, &TIM_InitStruct);
  LL_TIM_DisableARRPreload(TIM3);
  LL_TIM_SetClockSource(TIM3, LL_TIM_CLOCKSOURCE_INTERNAL);
  LL_TIM_SetTriggerOutput(TIM3, LL_TIM_TRGO_RESET);
  LL_TIM_DisableMasterSlaveMode(TIM3);

}

static void MX_TIM4_Init(void)
{

  TIM_MasterConfigTypeDef sMasterConfig = {0};
  TIM_OC_InitTypeDef sConfigOC = {0};

  htim4.Instance = TIM4;
  htim4.Init.Prescaler = 0;
  htim4.Init.CounterMode = TIM_COUNTERMODE_UP;
  htim4.Init.Period = 65535;
  htim4.Init.ClockDivision = TIM_CLOCKDIVISION_DIV1;
  htim4.Init.AutoReloadPreload = TIM_AUTORELOAD_PRELOAD_DISABLE;
  if (HAL_TIM_OC_Init(&htim4) != HAL_OK)
  {
    Error_Handler();
  }
  sMasterConfig.MasterOutputTrigger = TIM_TRGO_RESET;
  sMasterConfig.MasterSlaveMode = TIM_MASTERSLAVEMODE_DISABLE;
  if (HAL_TIMEx_MasterConfigSynchronization(&htim4, &sMasterConfig) != HAL_OK)
  {
    Error_Handler();
  }
  sConfigOC.OCMode = TIM_OCMODE_TIMING;
  sConfigOC.Pulse = 0;
  sConfigOC.OCPolarity = TIM_OCPOLARITY_HIGH;
  sConfigOC.OCFastMode = TIM_OCFAST_DISABLE;
  if (HAL_TIM_OC_ConfigChannel(&htim4, &sConfigOC, TIM_CHANNEL_1) != HAL_OK)
  {
    Error_Handler();
  }
  if (HAL_TIM_OC_ConfigChannel(&htim4, &sConfigOC, TIM_CHANNEL_2) != HAL_OK)
  {
    Error_Handler();
  }
  if (HAL_TIM_OC_ConfigChannel(&htim4, &sConfigOC, TIM_CHANNEL_3) != HAL_OK)
  {
    Error_Handler();
  }
  if (HAL_TIM_OC_ConfigChannel(&htim4, &sConfigOC, TIM_CHANNEL_4) != HAL_OK)
  {
    Error_Handler();
  }
  HAL_TIM_MspPostInit(&htim4);

}

static void MX_USART1_UART_Init(void)
{

  LL_USART_InitTypeDef USART_InitStruct = {0};

  LL_GPIO_InitTypeDef GPIO_InitStruct = {0};

  /* Peripheral clock enable */
  LL_APB2_GRP1_EnableClock(LL_APB2_GRP1_PERIPH_USART1);

  LL_AHB1_GRP1_EnableClock(LL_AHB1_GRP1_PERIPH_GPIOA);
  /**USART1 GPIO Configuration
  PA9   ------> USART1_TX
  PA10   ------> USART1_RX
  */
  GPIO_InitStruct.Pin = EXP_RS485_TX_Pin|EXP_RS485_RX_Pin;
  GPIO_InitStruct.Mode = LL_GPIO_MODE_ALTERNATE;
  GPIO_InitStruct.Speed = LL_GPIO_SPEED_FREQ_VERY_HIGH;
  GPIO_InitStruct.OutputType = LL_GPIO_OUTPUT_PUSHPULL;
  GPIO_InitStruct.Pull = LL_GPIO_PULL_NO;
  GPIO_InitStruct.Alternate = LL_GPIO_AF_7;
  LL_GPIO_Init(GPIOA, &GPIO_InitStruct);

  /* USART1 interrupt Init */
  NVIC_SetPriority(USART1_IRQn, NVIC_EncodePriority(NVIC_GetPriorityGrouping(),0, 0));
  NVIC_EnableIRQ(USART1_IRQn);

  USART_InitStruct.BaudRate = 115200;
  USART_InitStruct.DataWidth = LL_USART_DATAWIDTH_8B;
  USART_InitStruct.StopBits = LL_USART_STOPBITS_1;
  USART_InitStruct.Parity = LL_USART_PARITY_NONE;
  USART_InitStruct.TransferDirection = LL_USART_DIRECTION_TX_RX;
  USART_InitStruct.HardwareFlowControl = LL_USART_HWCONTROL_NONE;
  USART_InitStruct.OverSampling = LL_USART_OVERSAMPLING_16;
  LL_USART_Init(USART1, &USART_InitStruct);
  LL_USART_ConfigAsyncMode(USART1);
  LL_USART_Enable(USART1);

}

static void MX_USART6_UART_Init(void)
{

  LL_USART_InitTypeDef USART_InitStruct = {0};

  LL_GPIO_InitTypeDef GPIO_InitStruct = {0};

  /* Peripheral clock enable */
  LL_APB2_GRP1_EnableClock(LL_APB2_GRP1_PERIPH_USART6);

  LL_AHB1_GRP1_EnableClock(LL_AHB1_GRP1_PERIPH_GPIOC);
  /**USART6 GPIO Configuration
  PC6   ------> USART6_TX
  PC7   ------> USART6_RX
  */
  GPIO_InitStruct.Pin = EXP_UART_TX_Pin|EXP_UART_RX_Pin;
  GPIO_InitStruct.Mode = LL_GPIO_MODE_ALTERNATE;
  GPIO_InitStruct.Speed = LL_GPIO_SPEED_FREQ_VERY_HIGH;
  GPIO_InitStruct.OutputType = LL_GPIO_OUTPUT_PUSHPULL;
  GPIO_InitStruct.Pull = LL_GPIO_PULL_NO;
  GPIO_InitStruct.Alternate = LL_GPIO_AF_8;
  LL_GPIO_Init(GPIOC, &GPIO_InitStruct);

  /* USART6 interrupt Init */
  NVIC_SetPriority(USART6_IRQn, NVIC_EncodePriority(NVIC_GetPriorityGrouping(),0, 0));
  NVIC_EnableIRQ(USART6_IRQn);

  USART_InitStruct.BaudRate = 115200;
  USART_InitStruct.DataWidth = LL_USART_DATAWIDTH_8B;
  USART_InitStruct.StopBits = LL_USART_STOPBITS_1;
  USART_InitStruct.Parity = LL_USART_PARITY_NONE;
  USART_InitStruct.TransferDirection = LL_USART_DIRECTION_TX_RX;
  USART_InitStruct.HardwareFlowControl = LL_USART_HWCONTROL_NONE;
  USART_InitStruct.OverSampling = LL_USART_OVERSAMPLING_16;
  LL_USART_Init(USART6, &USART_InitStruct);
  LL_USART_ConfigAsyncMode(USART6);
  LL_USART_Enable(USART6);

}

static void MX_DMA_Init(void)
{

  /* Init with LL driver */
  /* DMA controller clock enable */
  LL_AHB1_GRP1_EnableClock(LL_AHB1_GRP1_PERIPH_DMA2);

  /* DMA interrupt init */
  /* DMA2_Stream0_IRQn interrupt configuration */
  NVIC_SetPriority(DMA2_Stream0_IRQn, NVIC_EncodePriority(NVIC_GetPriorityGrouping(),0, 0));
  NVIC_EnableIRQ(DMA2_Stream0_IRQn);

}

static void MX_GPIO_Init(void)
{
  LL_GPIO_InitTypeDef GPIO_InitStruct = {0};

  /* GPIO Ports Clock Enable */
  LL_AHB1_GRP1_EnableClock(LL_AHB1_GRP1_PERIPH_GPIOE);
  LL_AHB1_GRP1_EnableClock(LL_AHB1_GRP1_PERIPH_GPIOC);
  LL_AHB1_GRP1_EnableClock(LL_AHB1_GRP1_PERIPH_GPIOH);
  LL_AHB1_GRP1_EnableClock(LL_AHB1_GRP1_PERIPH_GPIOA);
  LL_AHB1_GRP1_EnableClock(LL_AHB1_GRP1_PERIPH_GPIOB);
  LL_AHB1_GRP1_EnableClock(LL_AHB1_GRP1_PERIPH_GPIOD);

  /**/
  LL_GPIO_ResetOutputPin(GPIOE, TEC_3_SWEN_Pin|TEC_4_SWEN_Pin|TEC_2_SWEN_Pin|TEC_1_SWEN_Pin
                          |TEC_1_EN_Pin|LED_G_Pin|LED_B_Pin);

  /**/
  LL_GPIO_ResetOutputPin(GPIOC, TEC_2_EN_Pin|TEC_3_EN_Pin|TEC_4_EN_Pin);

  /**/
  LL_GPIO_ResetOutputPin(WD_DONE_GPIO_Port, WD_DONE_Pin);

  /**/
  LL_GPIO_ResetOutputPin(GPIOD, EXP_RS485_NRE_Pin|FRAM_CS_Pin|EF_5_EN_Pin|TEC_ADC_CS_Pin);

  /**/
  LL_GPIO_ResetOutputPin(GPIOB, SENSOR2_EN_Pin|SENSOR1_EN_Pin);

  /**/
  LL_GPIO_SetOutputPin(GPIOE, LASER_DAC_CS_Pin|LASER_SW_EXT_CS_Pin|LASER_SW_INT_CS_Pin|LASER_DAC_LATCH_Pin
                          |TEC_2_CS_Pin|TEC_1_CS_Pin);

  /**/
  LL_GPIO_SetOutputPin(GPIOB, EXP_RS485_DE_Pin|TEC_4_CS_Pin|TEC_3_CS_Pin);

  /**/
  LL_GPIO_SetOutputPin(GPIOD, PHOTO_PD_CS_Pin|PHOTO_ADC_CS_Pin|PHOTO_ADC_CONV_Pin);

  /**/
  GPIO_InitStruct.Pin = TEC_3_SWEN_Pin|TEC_1_SWEN_Pin;
  GPIO_InitStruct.Mode = LL_GPIO_MODE_OUTPUT;
  GPIO_InitStruct.Speed = LL_GPIO_SPEED_FREQ_LOW;
  GPIO_InitStruct.OutputType = LL_GPIO_OUTPUT_PUSHPULL;
  GPIO_InitStruct.Pull = LL_GPIO_PULL_DOWN;
  LL_GPIO_Init(GPIOE, &GPIO_InitStruct);

  /**/
  GPIO_InitStruct.Pin = TEC_4_SWEN_Pin|TEC_2_SWEN_Pin|TEC_1_EN_Pin|LED_G_Pin
                          |LED_B_Pin|LASER_DAC_CS_Pin|LASER_SW_EXT_CS_Pin|LASER_SW_INT_CS_Pin
                          |LASER_DAC_LATCH_Pin|TEC_2_CS_Pin|TEC_1_CS_Pin;
  GPIO_InitStruct.Mode = LL_GPIO_MODE_OUTPUT;
  GPIO_InitStruct.Speed = LL_GPIO_SPEED_FREQ_LOW;
  GPIO_InitStruct.OutputType = LL_GPIO_OUTPUT_PUSHPULL;
  GPIO_InitStruct.Pull = LL_GPIO_PULL_NO;
  LL_GPIO_Init(GPIOE, &GPIO_InitStruct);

  /**/
  GPIO_InitStruct.Pin = TEC_2_EN_Pin|TEC_3_EN_Pin|TEC_4_EN_Pin;
  GPIO_InitStruct.Mode = LL_GPIO_MODE_OUTPUT;
  GPIO_InitStruct.Speed = LL_GPIO_SPEED_FREQ_LOW;
  GPIO_InitStruct.OutputType = LL_GPIO_OUTPUT_PUSHPULL;
  GPIO_InitStruct.Pull = LL_GPIO_PULL_NO;
  LL_GPIO_Init(GPIOC, &GPIO_InitStruct);

  /**/
  GPIO_InitStruct.Pin = WD_DONE_Pin;
  GPIO_InitStruct.Mode = LL_GPIO_MODE_OUTPUT;
  GPIO_InitStruct.Speed = LL_GPIO_SPEED_FREQ_LOW;
  GPIO_InitStruct.OutputType = LL_GPIO_OUTPUT_PUSHPULL;
  GPIO_InitStruct.Pull = LL_GPIO_PULL_NO;
  LL_GPIO_Init(WD_DONE_GPIO_Port, &GPIO_InitStruct);

  /**/
  GPIO_InitStruct.Pin = EF_12_AUX_Pin;
  GPIO_InitStruct.Mode = LL_GPIO_MODE_INPUT;
  GPIO_InitStruct.Pull = LL_GPIO_PULL_NO;
  LL_GPIO_Init(EF_12_AUX_GPIO_Port, &GPIO_InitStruct);

  /**/
  GPIO_InitStruct.Pin = EXP_RS485_DE_Pin|SENSOR2_EN_Pin|SENSOR1_EN_Pin|TEC_4_CS_Pin
                          |TEC_3_CS_Pin;
  GPIO_InitStruct.Mode = LL_GPIO_MODE_OUTPUT;
  GPIO_InitStruct.Speed = LL_GPIO_SPEED_FREQ_LOW;
  GPIO_InitStruct.OutputType = LL_GPIO_OUTPUT_PUSHPULL;
  GPIO_InitStruct.Pull = LL_GPIO_PULL_NO;
  LL_GPIO_Init(GPIOB, &GPIO_InitStruct);

  /**/
  GPIO_InitStruct.Pin = EXP_RS485_NRE_Pin|PHOTO_PD_CS_Pin|PHOTO_ADC_CS_Pin|PHOTO_ADC_CONV_Pin
                          |FRAM_CS_Pin|EF_5_EN_Pin|TEC_ADC_CS_Pin;
  GPIO_InitStruct.Mode = LL_GPIO_MODE_OUTPUT;
  GPIO_InitStruct.Speed = LL_GPIO_SPEED_FREQ_LOW;
  GPIO_InitStruct.OutputType = LL_GPIO_OUTPUT_PUSHPULL;
  GPIO_InitStruct.Pull = LL_GPIO_PULL_NO;
  LL_GPIO_Init(GPIOD, &GPIO_InitStruct);

  /**/
  GPIO_InitStruct.Pin = PHOTO_ADC_EOC_Pin;
  GPIO_InitStruct.Mode = LL_GPIO_MODE_INPUT;
  GPIO_InitStruct.Pull = LL_GPIO_PULL_UP;
  LL_GPIO_Init(PHOTO_ADC_EOC_GPIO_Port, &GPIO_InitStruct);

  /**/
  GPIO_InitStruct.Pin = IRQ1_Pin;
  GPIO_InitStruct.Mode = LL_GPIO_MODE_INPUT;
  GPIO_InitStruct.Pull = LL_GPIO_PULL_NO;
  LL_GPIO_Init(IRQ1_GPIO_Port, &GPIO_InitStruct);

  /**/
  GPIO_InitStruct.Pin = IRQ0_Pin;
  GPIO_InitStruct.Mode = LL_GPIO_MODE_INPUT;
  GPIO_InitStruct.Pull = LL_GPIO_PULL_NO;
  LL_GPIO_Init(IRQ0_GPIO_Port, &GPIO_InitStruct);

  /**/
  GPIO_InitStruct.Pin = FF_5_AUX_Pin;
  GPIO_InitStruct.Mode = LL_GPIO_MODE_INPUT;
  GPIO_InitStruct.Pull = LL_GPIO_PULL_NO;
  LL_GPIO_Init(FF_5_AUX_GPIO_Port, &GPIO_InitStruct);

}

/* USER CODE BEGIN 4 */
PRINTF_USART6 {
    while (!LL_USART_IsActiveFlag_TXE(USART6));
    LL_USART_TransmitData8(USART6, data);
    return data;
}
/* USER CODE END 4 */

void Error_Handler(void)
{
  __disable_irq();
  while (1)
  {
  }
}
